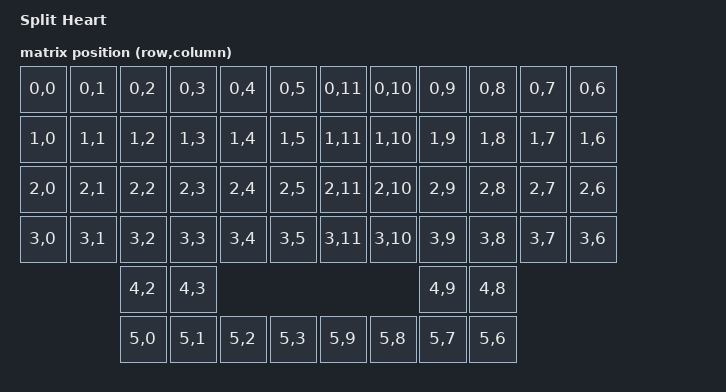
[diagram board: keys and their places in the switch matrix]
// This file was generated from a template. Edit it to match your keyboard.
// See https://docs.zephyrproject.org/3.5.0/hardware/porting/board_porting.html
// and https://zmk.dev/docs/development/hardware-integration/new-shield for more
// instructions.

/dts-v1/;
#include <nordic/nrf52840_qiaa.dtsi>
#include <dt-bindings/zmk/matrix_transform.h>
#include "split_heart-layouts.dtsi"


/ {
    model = "Split Heart";
    compatible = "split_heart";

    chosen {
        zephyr,code-partition = &code_partition;
        //zephyr,console = &cdc_acm_uart;
        zephyr,sram = &sram0;
        zephyr,flash = &flash0;
        zmk,kscan = &kscan0;
        zmk,battery = &vbatt;
        zmk,matrix_transform = &default_transform;
        zmk,physical-layout = &default_layout;
    };

    
    kscan0: kscan {
        compatible = "zmk,kscan-gpio-matrix";
        wakeup-source;
        diode-direction = "col2row";
    };

    default_transform: keymap_transform_0 {
        compatible = "zmk,matrix-transform";  
        columns = <12>;
        rows = <6>;

            // | SW1  | SW2  | SW3  | SW4  | SW5  | SW6  |   | SW6  | SW5  | SW4  | SW3  | SW2  | SW1  |
            // | SW7  | SW8  | SW9  | SW10 | SW11 | SW12 |   | SW12 | SW11 | SW10 | SW9  | SW8  | SW7  |
            // | SW13 | SW14 | SW15 | SW16 | SW17 | SW18 |   | SW18 | SW17 | SW16 | SW15 | SW14 | SW13 |
            // | SW19 | SW20 | SW21 | SW22 | SW23 | SW24 |   | SW24 | SW23 | SW22 | SW21 | SW20 | SW19 |
            // |      |      | SW25 | SW26 |      |      |   |      |      | SW26 | SW25 |      |      |
            // | SW27 | SW28 | SW29 | SW30 |      |      |   |      |      | SW30 | SW29 | SW28 | SW27 |
        map = <
            RC(0,0) RC(0,1) RC(0,2) RC(0,3) RC(0,4) RC(0,5)  RC(0,11) RC(0,10) RC(0,9) RC(0,8) RC(0,7) RC(0,6)
            RC(1,0) RC(1,1) RC(1,2) RC(1,3) RC(1,4) RC(1,5)  RC(1,11) RC(1,10) RC(1,9) RC(1,8) RC(1,7) RC(1,6)
            RC(2,0) RC(2,1) RC(2,2) RC(2,3) RC(2,4) RC(2,5)  RC(2,11) RC(2,10) RC(2,9) RC(2,8) RC(2,7) RC(2,6)
            RC(3,0) RC(3,1) RC(3,2) RC(3,3) RC(3,4) RC(3,5)  RC(3,11) RC(3,10) RC(3,9) RC(3,8) RC(3,7) RC(3,6)
                            RC(4,2) RC(4,3)                                    RC(4,9) RC(4,8) 
                            RC(5,0) RC(5,1) RC(5,2) RC(5,3)  RC(5,9)  RC(5,8)  RC(5,7) RC(5,6) 
        >;
    };


    // leds {
    //     compatible = "gpio-leds";
    //     led_green: led_0 {
    //         gpios = <&gpio0 4 GPIO_ACTIVE_LOW>;  // P0.04, Active LOW (3.8V에서 당김)
    //         label = "Green LED";
    //     };
    //     led_red: led_1 {
    //         gpios = <&gpio0 6 GPIO_ACTIVE_LOW>;   // P0.06, Active LOW
    //         label = "Red LED";
    //     };
    //     led_blue: led_2 {
    //         gpios = <&gpio0 8 GPIO_ACTIVE_LOW>;   // P0.08, Active LOW
    //         label = "Blue LED";
    //     };
    // };

    // If you are powering the SoC from the VDDH pin, uncomment this block.
    // Otherwise, delete it.

    vbatt: vbatt {
        compatible = "zmk,battery-nrf-vddh";
    };

    // If you are powering the SoC from the VDD pin and you have a voltage divider
    // routed to an analog pin to read the battery voltage, uncomment this block
    // and assign the correct ADC channel and resistance values.
    // Otherwise, delete it.

    // vbatt: vbatt {
    //     compatible = "voltage-divider";
    //     io-channels = <&adc 2>;
    //     output-ohms = <2000000>;
    //     full-ohms = <(2000000 + 806000)>;
    // };
};

&adc {
    status = "okay";
};

&gpiote {
    status = "okay";
};

&gpio0 {
    status = "okay";
};

&gpio1 {
    status = "okay";
};

zephyr_udc0: &usbd {
    status = "okay";
};
// &uart0 {
//     compatible = "nordic,nrf-uarte";
//     current-speed = <115200>;
//     pinctrl-0 = <&uart0_default>;
//     pinctrl-1 = <&uart0_sleep>;
//     pinctrl-names = "default", "sleep";
// };

&flash0 {
    /*
     * For more information, see:
     * http://docs.zephyrproject.org/latest/devices/dts/flash_partitions.html
     */
    partitions {
        compatible = "fixed-partitions";
        #address-cells = <1>;
        #size-cells = <1>;

        sd_partition: partition@0 {
            reg = <0x00000000 0x00026000>;
        };
        code_partition: partition@26000 {
            reg = <0x00026000 0x000c6000>;
        };

        /*
         * The flash starting at 0x000ec000 and ending at
         * 0x000f3fff is reserved for use by the application.
         */

        /*
         * Storage partition will be used by FCB/LittleFS/NVS
         * if enabled.
         */
        storage_partition: partition@ec000 {
            reg = <0x000ec000 0x00008000>;
        };

        boot_partition: partition@f4000 {
            reg = <0x000f4000 0x0000c000>;
        };
    };
};
